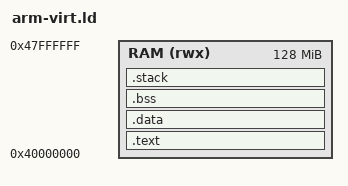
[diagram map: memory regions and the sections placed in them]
ENTRY(_start)

MEMORY
{
    RAM (rwx) : ORIGIN = 0x40000000, LENGTH = 128M
}

SECTIONS
{
    .text : ALIGN(4)
    {
        *(.text.entry)
        *(.text .text.*)
        *(.rodata .rodata.*)
    } > RAM

    .data : ALIGN(4)
    {
        _sdata = .;
        *(.data .data.*)
        _edata = .;
    } > RAM AT > RAM

    _sidata = LOADADDR(.data);

    .bss : ALIGN(4)
    {
        _sbss = .;
        *(.bss .bss.*)
        *(COMMON)
        _ebss = .;
    } > RAM

    .stack : ALIGN(16)
    {
        . += 0x8000; /* 32 KB Stack */
        _estack = .;
    } > RAM

    /DISCARD/ :
    {
        *(.comment)
        *(.note*)
    }
}
